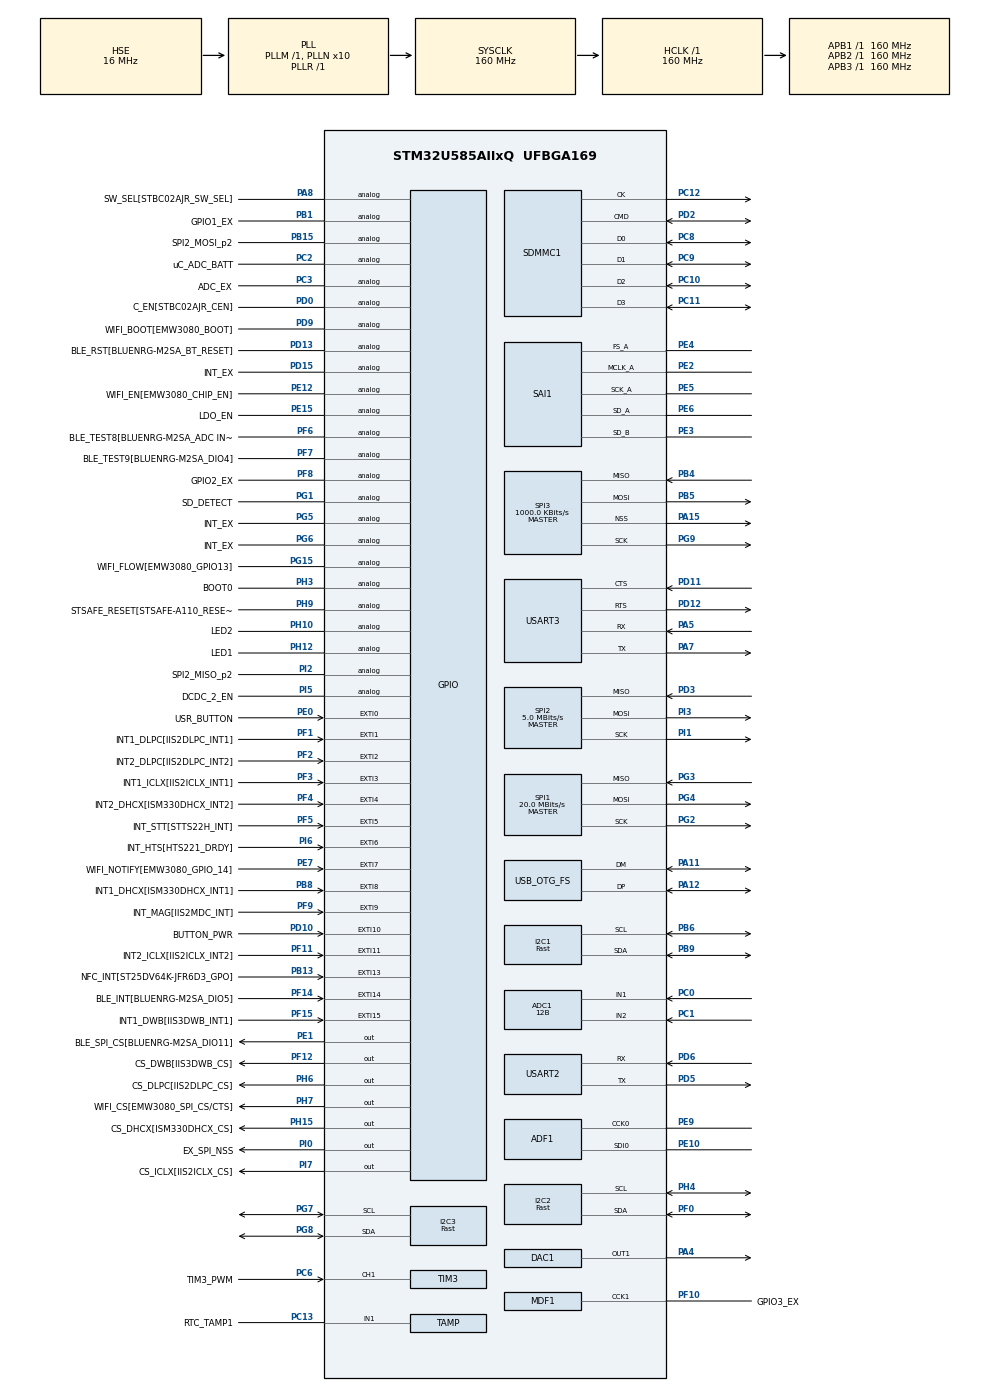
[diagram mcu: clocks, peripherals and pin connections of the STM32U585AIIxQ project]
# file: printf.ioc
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ADC1.ContinuousConvMode=ENABLE
ADC1.ConversionDataManagement=ADC_CONVERSIONDATA_MDF
ADC1.EnableInjectedConversion=DISABLE
ADC1.EnableRegularConversion=DISABLE
ADC1.NbrOfConversion=1
ADC1.Overrun=ADC_OVR_DATA_OVERWRITTEN
ADC1.Resolution=ADC_RESOLUTION_12B
ADC1.master=1
ADF1.MDF_COMPARAM_ActivationClockTrigger=ENABLE
ADF1.MDF_COMPARAM_ActivationOutputClock=ENABLE
ADF1.MDF_COMPARAM_Clock_Source=MDF_CLOCK_TRIG_TRGO
ADF1.MDF_COMPARAM_Divider=5
ADF1.MDF_DFLT0_AcquisitionMode=MDF_MODE_SYNC_CONT
ADF1.MDF_DFLT0_CIC_Mode=MDF_ONE_FILTER_SINC5
ADF1.MDF_DFLT0_Decimation=16
ADF1.MDF_DFLT0_Gain=1
ADF1.MDF_DFLT0_HighPassFilterActivation=ENABLE
ADF1.MDF_DFLT0_ReshapeFilterActivation=ENABLE
ADF1.MDF_SITF0_Mode_Display=MDF_SITF_NORMAL_SPI_MODE
ADF1.MDF_SITF0_Threshold=31
CORTEX_M33_NS.userName=CORTEX_M33
DAC1.DAC_Channel-DAC_OUT1_ExtAndInt=DAC_CHANNEL_1
GPDMA1.CIRCULARMODE_GPDMACH4=ENABLE
GPDMA1.CIRCULARMODE_GPDMACH5=ENABLE
GPDMA1.DATAALIGNEMENT_GPDMACH4=DMA_DATA_UNPACK
GPDMA1.DATAALIGNEMENT_GPDMACH5=DMA_DATA_UNPACK
GPDMA1.DATAHANDLING_GPDMACH4=ENABLE
GPDMA1.DATAHANDLING_GPDMACH5=ENABLE
GPDMA1.DESTDATAWIDTH_GPDMACH4=DMA_DEST_DATAWIDTH_HALFWORD
GPDMA1.DESTDATAWIDTH_GPDMACH5=DMA_DEST_DATAWIDTH_HALFWORD
GPDMA1.DESTINC_GPDMACH0=DMA_DINC_INCREMENTED
GPDMA1.DESTINC_GPDMACH2=DMA_DINC_INCREMENTED
GPDMA1.DESTINC_GPDMACH4=DMA_DINC_INCREMENTED
GPDMA1.DESTINC_GPDMACH5=DMA_DINC_INCREMENTED
GPDMA1.DIRECTION_GPDMACH1=DMA_MEMORY_TO_PERIPH
GPDMA1.DIRECTION_GPDMACH3=DMA_MEMORY_TO_PERIPH
GPDMA1.IPHANDLE_GPDMACH0-SIMPLEREQUEST_GPDMACH0=__NULL
GPDMA1.IPHANDLE_GPDMACH1-SIMPLEREQUEST_GPDMACH1=__NULL
GPDMA1.IPHANDLE_GPDMACH2-SIMPLEREQUEST_GPDMACH2=__NULL
GPDMA1.IPHANDLE_GPDMACH3-SIMPLEREQUEST_GPDMACH3=__NULL
GPDMA1.IPHANDLE_GPDMACH4-SIMPLEREQUEST_GPDMACH4=__NULL
GPDMA1.IPHANDLE_GPDMACH5-SIMPLEREQUEST_GPDMACH5=__NULL
GPDMA1.PRIORITY_LL_CIRCULAR_GPDMACH4=DMA_HIGH_PRIORITY
GPDMA1.PRIORITY_LL_CIRCULAR_GPDMACH5=DMA_HIGH_PRIORITY
GPDMA1.REQUEST_GPDMACH0=GPDMA1_REQUEST_SPI2_RX
GPDMA1.REQUEST_GPDMACH1=GPDMA1_REQUEST_SPI2_TX
GPDMA1.REQUEST_GPDMACH2=GPDMA1_REQUEST_I2C2_RX
GPDMA1.REQUEST_GPDMACH3=GPDMA1_REQUEST_I2C2_TX
GPDMA1.REQUEST_GPDMACH4=GPDMA1_REQUEST_MDF1_FLT0
GPDMA1.REQUEST_GPDMACH5=GPDMA1_REQUEST_ADF1_FLT0
GPDMA1.SRCDATAWIDTH_GPDMACH4=DMA_SRC_DATAWIDTH_HALFWORD
GPDMA1.SRCDATAWIDTH_GPDMACH5=DMA_SRC_DATAWIDTH_HALFWORD
GPDMA1.SRCINC_GPDMACH1=DMA_SINC_INCREMENTED
GPDMA1.SRCINC_GPDMACH3=DMA_SINC_INCREMENTED
GPDMA1.TRANSFERALLOCATEDPORTDEST_GPDMACH5=DMA_DEST_ALLOCATED_PORT1
GPDMA1.TRANSFEREVENTMODE_LL_CIRCULAR_GPDMACH4=DMA_TCEM_LAST_LL_ITEM_TRANSFER
GPDMA1.TRANSFEREVENTMODE_LL_CIRCULAR_GPDMACH5=DMA_TCEM_LAST_LL_ITEM_TRANSFER
GPDMA1.TRIGGERPOLARITY_GPDMACH0=DMA_TRIG_POLARITY_MASKED
GPDMA1.TRIGGERPOLARITY_GPDMACH1=DMA_TRIG_POLARITY_MASKED
I2C1.I2C_Speed_Mode=I2C_Fast
I2C1.Timing=0x00F07BFF
I2C2.I2C_Speed_Mode=I2C_Fast
I2C2.Timing=0x00F07BFF
I2C3.I2C_Speed_Mode=I2C_Fast
I2C3.Timing=0x00F07BFF
MDF1.MDF_DFLT0_CIC_Mode=MDF_ONE_FILTER_SINC5
MDF1.MDF_DFLT0_Decimation=4
MDF1.MDF_DFLT0_Gain=4
MDF1.MDF_DFLT0_HighPassFilterActivation=ENABLE
Mcu.Family=STM32U5
Mcu.Name=STM32U585AIIxQ
Mcu.Package=UFBGA169
NVIC.EXTI0_IRQn=true\:7\:0\:true\:false\:true\:true\:true\:true
NVIC.EXTI10_IRQn=true\:7\:0\:true\:false\:true\:true\:true\:true
NVIC.EXTI11_IRQn=true\:7\:0\:true\:false\:true\:true\:true\:true
NVIC.EXTI13_IRQn=true\:7\:0\:true\:false\:true\:true\:true\:true
NVIC.EXTI14_IRQn=true\:7\:0\:true\:false\:true\:true\:true\:true
NVIC.EXTI1_IRQn=true\:7\:0\:true\:false\:true\:true\:true\:true
NVIC.EXTI2_IRQn=true\:7\:0\:true\:false\:true\:true\:true\:true
NVIC.EXTI3_IRQn=true\:7\:0\:true\:false\:true\:true\:true\:true
NVIC.EXTI4_IRQn=true\:7\:0\:true\:false\:true\:true\:true\:true
NVIC.EXTI5_IRQn=true\:7\:0\:true\:false\:true\:true\:true\:true
NVIC.EXTI6_IRQn=true\:7\:0\:true\:false\:true\:true\:true\:true
NVIC.EXTI7_IRQn=true\:7\:0\:true\:false\:true\:true\:true\:true
NVIC.EXTI8_IRQn=true\:7\:0\:true\:false\:true\:true\:true\:true
NVIC.EXTI9_IRQn=true\:7\:0\:true\:false\:true\:true\:true\:true
NVIC.GPDMA1_Channel0_IRQn=true\:0\:0\:false\:false\:true\:true\:true\:true
NVIC.GPDMA1_Channel1_IRQn=true\:0\:0\:false\:false\:true\:true\:true\:true
NVIC.GPDMA1_Channel2_IRQn=true\:0\:0\:false\:false\:true\:false\:true\:true
NVIC.GPDMA1_Channel3_IRQn=true\:0\:0\:false\:false\:true\:false\:true\:true
NVIC.GPDMA1_Channel4_IRQn=true\:0\:0\:false\:false\:true\:false\:true\:true
NVIC.GPDMA1_Channel5_IRQn=true\:0\:0\:false\:false\:true\:false\:true\:true
NVIC.PriorityGroup=NVIC_PRIORITYGROUP_4
NVIC.SPI2_IRQn=true\:0\:0\:false\:false\:true\:false\:true\:true
PA11.GPIO_Speed=GPIO_SPEED_FREQ_VERY_HIGH
PA11.Mode=Device_Only
PA11.Signal=USB_OTG_FS_DM
PA12.GPIO_Speed=GPIO_SPEED_FREQ_VERY_HIGH
PA12.Mode=Device_Only
PA12.PinAttribute=Free
PA12.Signal=USB_OTG_FS_DP
PA13\ (JTMS/SWDIO).Mode=Trace_Asynchronous_SW
PA13\ (JTMS/SWDIO).Signal=DEBUG_JTMS-SWDIO
PA14\ (JTCK/SWCLK).Mode=Trace_Asynchronous_SW
PA14\ (JTCK/SWCLK).Signal=DEBUG_JTCK-SWCLK
PA15\ (JTDI).Mode=NSS_Signal_Hard_Output
PA15\ (JTDI).Signal=SPI3_NSS
PA4.Signal=COMP_DAC11_group
PA5.Mode=Asynchronous
PA5.PinAttribute=Free
PA5.Signal=USART3_RX
PA7.Mode=Asynchronous
PA7.Signal=USART3_TX
PA8.GPIO_Label=SW_SEL[STBC02AJR_SW_SEL]
PA8.PinAttribute=Free
PA8.Signal=GPIO_Analog
PB1.GPIO_Label=GPIO1_EX
PB1.Signal=GPIO_Analog
PB13.GPIO_Label=NFC_INT[ST25DV64K-JFR6D3_GPO]
PB13.Signal=GPXTI13
PB15.GPIO_Label=SPI2_MOSI_p2
PB15.Signal=GPIO_Analog
PB3\ (JTDO/TRACESWO).Mode=Trace_Asynchronous_SW
PB3\ (JTDO/TRACESWO).Signal=DEBUG_JTDO-SWO
PB4\ (NJTRST).Mode=Full_Duplex_Master
PB4\ (NJTRST).Signal=SPI3_MISO
PB5.Mode=Full_Duplex_Master
PB5.Signal=SPI3_MOSI
PB6.Mode=I2C
PB6.Signal=I2C1_SCL
PB8.GPIO_Label=INT1_DHCX[ISM330DHCX_INT1]
PB8.Signal=GPXTI8
PB9.Mode=I2C
PB9.Signal=I2C1_SDA
PC0.Mode=IN1-Single-Ended
PC0.Signal=ADC1_IN1
PC1.Mode=IN2-Single-Ended
PC1.Signal=ADC1_IN2
PC10.Mode=SD_4_bits_Wide_bus
PC10.Signal=SDMMC1_D2
PC11.Mode=SD_4_bits_Wide_bus
PC11.Signal=SDMMC1_D3
PC12.Mode=SD_4_bits_Wide_bus
PC12.Signal=SDMMC1_CK
PC13.GPIO_Label=RTC_TAMP1
PC13.Mode=Tamper_1_enabled0
PC13.Signal=TAMP_IN1
PC14-OSC32_IN\ (PC14).Mode=LSE-External-Oscillator
PC14-OSC32_IN\ (PC14).Signal=RCC_OSC32_IN
PC15-OSC32_OUT\ (PC15).Mode=LSE-External-Oscillator
PC15-OSC32_OUT\ (PC15).Signal=RCC_OSC32_OUT
PC2.GPIO_Label=uC_ADC_BATT
PC2.Signal=GPIO_Analog
PC3.GPIO_Label=ADC_EX
PC3.PinAttribute=Free
PC3.Signal=GPIO_Analog
PC6.GPIO_Label=TIM3_PWM
PC6.Signal=S_TIM3_CH1
PC8.Mode=SD_4_bits_Wide_bus
PC8.PinAttribute=Free
PC8.Signal=SDMMC1_D0
PC9.Mode=SD_4_bits_Wide_bus
PC9.PinAttribute=Free
PC9.Signal=SDMMC1_D1
PD0.GPIO_Label=C_EN[STBC02AJR_CEN]
PD0.Signal=GPIO_Analog
PD10.GPIO_Label=BUTTON_PWR
PD10.Signal=GPXTI10
PD11.Mode=CTS_RTS
PD11.Signal=USART3_CTS
PD12.Mode=CTS_RTS
PD12.Signal=USART3_RTS
PD13.GPIO_Label=BLE_RST[BLUENRG-M2SA_BT_RESET]
PD13.Signal=GPIO_Analog
PD15.GPIO_Label=INT_EX
PD15.PinAttribute=Free
PD15.Signal=GPIO_Analog
PD2.Mode=SD_4_bits_Wide_bus
PD2.Signal=SDMMC1_CMD
PD3.Mode=Full_Duplex_Master
PD3.Signal=SPI2_MISO
PD4.Signal=USART2_RTS
PD5.Mode=Asynchronous
PD5.Signal=USART2_TX
PD6.Mode=Asynchronous
PD6.Signal=USART2_RX
PD9.GPIO_Label=WIFI_BOOT[EMW3080_BOOT]
PD9.Signal=GPIO_Analog
PE0.GPIO_Label=USR_BUTTON
PE0.Signal=GPXTI0
PE1.GPIO_Label=BLE_SPI_CS[BLUENRG-M2SA_DIO11]
PE1.PinState=GPIO_PIN_SET
PE1.Signal=GPIO_Output
PE10.Mode=MOD_ADF_CCK
PE10.Signal=ADF1_SDI0
PE12.GPIO_Label=WIFI_EN[EMW3080_CHIP_EN]
PE12.Signal=GPIO_Analog
PE15.GPIO_Label=LDO_EN
PE15.Signal=GPIO_Analog
PE2.Mode=SAI_A_MasterWithClock
PE2.PinAttribute=Free
PE2.Signal=SAI1_MCLK_A
PE3.Mode=SAI_B_SyncSlave
PE3.Signal=SAI1_SD_B
PE4.Mode=SAI_A_MasterWithClock
PE4.Signal=SAI1_FS_A
PE5.Mode=SAI_A_MasterWithClock
PE5.Signal=SAI1_SCK_A
PE6.Mode=SAI_A_MasterWithClock
PE6.Signal=SAI1_SD_A
PE7.GPIO_Label=WIFI_NOTIFY[EMW3080_GPIO_14]
PE7.Signal=GPXTI7
PE9.Mode=MOD_MDF_CCK0
PE9.Signal=ADF1_CCK0
PF0.Mode=I2C
PF0.Signal=I2C2_SDA
PF1.GPIO_Label=INT1_DLPC[IIS2DLPC_INT1]
PF1.Signal=GPXTI1
PF10.GPIO_Label=GPIO3_EX
PF10.Mode=MOD_MDF_CCK1
PF10.Signal=MDF1_CCK1
PF11.GPIO_Label=INT2_ICLX[IIS2ICLX_INT2]
PF11.Signal=GPXTI11
PF12.GPIO_Label=CS_DWB[IIS3DWB_CS]
PF12.PinState=GPIO_PIN_SET
PF12.Signal=GPIO_Output
PF14.GPIO_Label=BLE_INT[BLUENRG-M2SA_DIO5]
PF14.Signal=GPXTI14
PF15.GPIO_Label=INT1_DWB[IIS3DWB_INT1]
PF15.Signal=GPXTI15
PF2.GPIO_Label=INT2_DLPC[IIS2DLPC_INT2]
PF2.Signal=GPXTI2
PF3.GPIO_Label=INT1_ICLX[IIS2ICLX_INT1]
PF3.PinAttribute=Free
PF3.Signal=GPXTI3
PF4.GPIO_Label=INT2_DHCX[ISM330DHCX_INT2]
PF4.PinAttribute=Free
PF4.Signal=GPXTI4
PF5.GPIO_Label=INT_STT[STTS22H_INT]
PF5.PinAttribute=Free
PF5.Signal=GPXTI5
PF6.GPIO_Label=BLE_TEST8[BLUENRG-M2SA_ADC IN 1]
PF6.Signal=GPIO_Analog
PF7.GPIO_Label=BLE_TEST9[BLUENRG-M2SA_DIO4]
PF7.PinAttribute=Free
PF7.Signal=GPIO_Analog
PF8.GPIO_Label=GPIO2_EX
PF8.Signal=GPIO_Analog
PF9.GPIO_Label=INT_MAG[IIS2MDC_INT]
PF9.PinAttribute=Free
PF9.Signal=GPXTI9
PG1.GPIO_Label=SD_DETECT
PG1.Signal=GPIO_Analog
PG15.GPIO_Label=WIFI_FLOW[EMW3080_GPIO13]
PG15.Signal=GPIO_Analog
PG2.Mode=Full_Duplex_Master
PG2.Signal=SPI1_SCK
PG3.Mode=Full_Duplex_Master
PG3.PinAttribute=Free
PG3.Signal=SPI1_MISO
PG4.Mode=Full_Duplex_Master
PG4.Signal=SPI1_MOSI
PG5.GPIO_Label=INT_EX
PG5.PinAttribute=Free
PG5.Signal=GPIO_Analog
PG6.GPIO_Label=INT_EX
PG6.Signal=GPIO_Analog
PG7.Mode=I2C
PG7.PinAttribute=Free
PG7.Signal=I2C3_SCL
PG8.Mode=I2C
PG8.Signal=I2C3_SDA
PG9.GPIO_PuPd=GPIO_PULLUP
PG9.Mode=Full_Duplex_Master
PG9.Signal=SPI3_SCK
PH0-OSC_IN\ (PH0).Mode=HSE-External-Oscillator
PH0-OSC_IN\ (PH0).Signal=RCC_OSC_IN
PH1-OSC_OUT\ (PH1).Mode=HSE-External-Oscillator
PH1-OSC_OUT\ (PH1).Signal=RCC_OSC_OUT
PH10.GPIO_Label=LED2
PH10.Signal=GPIO_Analog
PH12.GPIO_Label=LED1
PH12.Signal=GPIO_Analog
PH15.GPIO_Label=CS_DHCX[ISM330DHCX_CS]
PH15.PinState=GPIO_PIN_SET
PH15.Signal=GPIO_Output
PH3-BOOT0.GPIO_Label=BOOT0
PH3-BOOT0.Signal=GPIO_Analog
PH4.Mode=I2C
PH4.Signal=I2C2_SCL
PH6.GPIO_Label=CS_DLPC[IIS2DLPC_CS]
PH6.PinState=GPIO_PIN_SET
PH6.Signal=GPIO_Output
PH7.GPIO_Label=WIFI_CS[EMW3080_SPI_CS/CTS]
PH7.PinState=GPIO_PIN_SET
PH7.Signal=GPIO_Output
PH9.GPIO_Label=STSAFE_RESET[STSAFE-A110_RESET]
PH9.Signal=GPIO_Analog
PI0.GPIO_Label=EX_SPI_NSS
PI0.PinState=GPIO_PIN_SET
PI0.Signal=GPIO_Output
PI1.Mode=Full_Duplex_Master
PI1.Signal=SPI2_SCK
PI2.GPIO_Label=SPI2_MISO_p2
PI2.Signal=GPIO_Analog
PI3.Mode=Full_Duplex_Master
PI3.Signal=SPI2_MOSI
PI5.GPIO_Label=DCDC_2_EN
PI5.Signal=GPIO_Analog
PI6.GPIO_Label=INT_HTS[HTS221_DRDY]
PI6.PinAttribute=Free
PI6.Signal=GPXTI6
PI7.GPIO_Label=CS_ICLX[IIS2ICLX_CS]
PI7.PinState=GPIO_PIN_SET
PI7.Signal=GPIO_Output
ProjectManager.HeapSize=0x200
ProjectManager.StackSize=0x400
ProjectManager.TargetToolchain=STM32CubeIDE
RCC.ADCCLockSelection=RCC_ADCDACCLKSOURCE_PLL2
RCC.ADCFreq_Value=15360000
RCC.AHBFreq_Value=160000000
RCC.APB1Freq_Value=160000000
RCC.APB1TimFreq_Value=160000000
RCC.APB2Freq_Value=160000000
RCC.APB2TimFreq_Value=160000000
RCC.APB3Freq_Value=160000000
RCC.AdfClockSelection=RCC_ADF1CLKSOURCE_PLL3
RCC.CortexFreq_Value=160000000
RCC.DACCLockSelectionVirtual=RCC_DAC1CLKSOURCE_LSI
RCC.EPOD_VALUE=16000000
RCC.HCLKFreq_Value=160000000
RCC.HSE_VALUE=16000000
RCC.HSI48_VALUE=48000000
RCC.HSI_VALUE=16000000
RCC.LSIDIV_VALUE=32000
RCC.MSI_VALUE=4000000
RCC.MdfClockSelection=RCC_MDF1CLKSOURCE_PLL3
RCC.PLL1R=1
RCC.PLL2FRACN=0
RCC.PLL2M=2
RCC.PLL2N=48
RCC.PLL2Q=7
RCC.PLL2R=25
RCC.PLL2Source=RCC_PLLSOURCE_HSE
RCC.PLL3FRACN=0
RCC.PLL3M=2
RCC.PLL3N=48
RCC.PLL3Q=25
RCC.PLL3Source=RCC_PLLSOURCE_HSE
RCC.PLLFRACN=0
RCC.PLLN=10
RCC.PLLSourceVirtual=RCC_PLLSOURCE_HSE
RCC.SAI1CLockSelection=RCC_SAI1CLKSOURCE_PLL1
RCC.SDMMCClockSelection=RCC_SDMMCCLKSOURCE_CLK48
RCC.SPI2CLockSelection=RCC_SPI2CLKSOURCE_PCLK1
RCC.SPI3CLockSelection=RCC_SPI3CLKSOURCE_HSI
RCC.SYSCLKFreq_VALUE=160000000
RCC.SYSCLKSource=RCC_SYSCLKSOURCE_PLLCLK
RCC.USBFreq_Value=48000000
RCC.VCOOutputFreq_Value=160000000
SAI1.ErrorAudioFreq-SAI_A_MasterWithClock=-18.61 %
SAI1.Instance-SAI_A_MasterWithClock=SAI$Index_Block_A
SAI1.Instance-SAI_B_SyncSlave=SAI$Index_Block_B
SAI1.MckOutput-SAI_A_MasterWithClock=SAI_MCK_OUTPUT_ENABLE
SAI1.RealAudioFreq-SAI_A_MasterWithClock=156.25 KHz
SAI1.VirtualMode-SAI_A_MasterWithClock=VM_MASTER
SAI1.VirtualMode-SAI_B_SyncSlave=VM_SLAVE
SH.COMP_DAC11_group.0=DAC1_OUT1,DAC_OUT1_ExtAndInt
SH.S_TIM3_CH1.0=TIM3_CH1,Input_Capture1_from_TI1
SPI1.BaudRatePrescaler=SPI_BAUDRATEPRESCALER_8
SPI1.CLKPhase=SPI_PHASE_2EDGE
SPI1.CLKPolarity=SPI_POLARITY_HIGH
SPI1.CalculateBaudRate=20.0 MBits/s
SPI1.DataSize=SPI_DATASIZE_8BIT
SPI1.Direction=SPI_DIRECTION_2LINES
SPI1.Mode=SPI_MODE_MASTER
SPI1.VirtualType=VM_MASTER
SPI2.BaudRatePrescaler=SPI_BAUDRATEPRESCALER_32
SPI2.CLKPhase=SPI_PHASE_2EDGE
SPI2.CLKPolarity=SPI_POLARITY_HIGH
SPI2.CRCCalculation=SPI_CRCCALCULATION_DISABLE
SPI2.CalculateBaudRate=5.0 MBits/s
SPI2.DataSize=SPI_DATASIZE_8BIT
SPI2.Direction=SPI_DIRECTION_2LINES
SPI2.Mode=SPI_MODE_MASTER
SPI2.TriggerSelection=SPI_GRP1_GPDMA_CH1_TCF_TRG
SPI2.TriggerState=SPI_AUTO_MODE_DISABLE
SPI2.VirtualType=VM_MASTER
SPI3.BaudRatePrescaler=SPI_BAUDRATEPRESCALER_16
SPI3.CLKPhase=SPI_PHASE_2EDGE
SPI3.CLKPolarity=SPI_POLARITY_HIGH
SPI3.CalculateBaudRate=1000.0 KBits/s
SPI3.DataSize=SPI_DATASIZE_8BIT
SPI3.Direction=SPI_DIRECTION_2LINES
SPI3.Mode=SPI_MODE_MASTER
SPI3.VirtualNSS=VM_NSSHARD
SPI3.VirtualType=VM_MASTER
TIM3.Channel-Input_Capture1_from_TI1=TIM_CHANNEL_1
USART2.ClockPrescaler=PRESCALER_DIV1
USART2.VirtualMode-Asynchronous=VM_ASYNC
USART2.WordLength=WORDLENGTH_8B
USART3.VirtualMode-Asynchronous=VM_ASYNC
USB_OTG_FS.Sof_enable-Device_Only=ENABLE
USB_OTG_FS.VirtualMode=Device_Only
VP_GPDMA1_VS_GPDMACH0.Mode=SIMPLEREQUEST_GPDMACH0
VP_GPDMA1_VS_GPDMACH1.Mode=SIMPLEREQUEST_GPDMACH1
VP_GPDMA1_VS_GPDMACH2.Mode=SIMPLEREQUEST_GPDMACH2
VP_GPDMA1_VS_GPDMACH3.Mode=SIMPLEREQUEST_GPDMACH3
VP_GPDMA1_VS_GPDMACH4.Mode=SIMPLEREQUEST_GPDMACH4
VP_GPDMA1_VS_GPDMACH5.Mode=SIMPLEREQUEST_GPDMACH5
VP_ICACHE_VS_ICACHE.Mode=DirectMappedCache
VP_LPBAMQUEUE_VS_QUEUE.Mode=QUEUEMODE
VP_LPBAM_VS_SIG1.Mode=SmartRun
VP_LPBAM_VS_SIG4.Mode=LPDMA1
VP_MDF1_VS_MDF_DFLT0.Mode=MOD_MDF_DFLT0
VP_PWR_VS_DBSignals.Mode=DisableDeadBatterySignals
VP_PWR_VS_LPOM.Mode=PowerOptimisation
VP_PWR_VS_SECSignals.Mode=Security/Privilege
VP_RTC_VS_RTC_Activate.Mode=RTC_Enabled
board=STEVAL-STWINBX1

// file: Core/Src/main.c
/* USER CODE BEGIN Header */
/**
  ******************************************************************************
  * @file           : main.c
  * @brief          : Main program body
  ******************************************************************************
  * @attention
  *
  * Copyright (c) 2023 STMicroelectronics.
  * All rights reserved.
  *
  * This software is licensed under terms that can be found in the LICENSE file
  * in the root directory of this software component.
  * If no LICENSE file comes with this software, it is provided AS-IS.
  *
  ******************************************************************************
  */
/* USER CODE END Header */
#include "main.h"

/* USER CODE BEGIN Includes */
#include <stdio.h>

/* USER CODE END Includes */

ADC_HandleTypeDef hadc1;

MDF_HandleTypeDef AdfHandle0;
MDF_FilterConfigTypeDef AdfFilterConfig0;
MDF_HandleTypeDef MdfHandle0;
MDF_FilterConfigTypeDef MdfFilterConfig0;
DMA_NodeTypeDef Node_GPDMA1_Channel5;
DMA_QListTypeDef List_GPDMA1_Channel5;
DMA_HandleTypeDef handle_GPDMA1_Channel5;
DMA_NodeTypeDef Node_GPDMA1_Channel4;
DMA_QListTypeDef List_GPDMA1_Channel4;
DMA_HandleTypeDef handle_GPDMA1_Channel4;

DAC_HandleTypeDef hdac1;

I2C_HandleTypeDef hi2c1;
I2C_HandleTypeDef hi2c2;
I2C_HandleTypeDef hi2c3;
DMA_HandleTypeDef handle_GPDMA1_Channel3;
DMA_HandleTypeDef handle_GPDMA1_Channel2;

RTC_HandleTypeDef hrtc;

SAI_HandleTypeDef hsai_BlockA1;
SAI_HandleTypeDef hsai_BlockB1;

SD_HandleTypeDef hsd1;

SPI_HandleTypeDef hspi1;
SPI_HandleTypeDef hspi2;
SPI_HandleTypeDef hspi3;
DMA_HandleTypeDef handle_GPDMA1_Channel1;
DMA_HandleTypeDef handle_GPDMA1_Channel0;

TIM_HandleTypeDef htim3;

UART_HandleTypeDef huart2;
UART_HandleTypeDef huart3;

PCD_HandleTypeDef hpcd_USB_OTG_FS;

void SystemClock_Config(void);
void PeriphCommonClock_Config(void);
static void SystemPower_Config(void);
static void MX_GPIO_Init(void);
static void MX_GPDMA1_Init(void);
static void MX_ADC1_Init(void);
static void MX_ADF1_Init(void);
static void MX_MDF1_Init(void);
static void MX_DAC1_Init(void);
static void MX_I2C1_Init(void);
static void MX_I2C2_Init(void);
static void MX_I2C3_Init(void);
static void MX_ICACHE_Init(void);
static void MX_RTC_Init(void);
static void MX_SAI1_Init(void);
static void MX_SDMMC1_SD_Init(void);
static void MX_SPI1_Init(void);
static void MX_SPI2_Init(void);
static void MX_SPI3_Init(void);
static void MX_TAMP_RTC_Init(void);
static void MX_TIM3_Init(void);
static void MX_USART2_UART_Init(void);
static void MX_USART3_UART_Init(void);
static void MX_USB_OTG_FS_PCD_Init(void);

/* USER CODE BEGIN 0 */
#ifdef __GNUC__
#define PUTCHAR_PROTOTYPE int __io_putchar(int ch)
#else
#define PUTCHAR_PROTOTYPE int fputc(int ch, FILE *f)
#endif

PUTCHAR_PROTOTYPE
{
  HAL_UART_Transmit(&huart2, (uint8_t *)&ch, 1, HAL_MAX_DELAY);
  return ch;
}

/* USER CODE END 0 */

int main(void)
{

  /* MCU Configuration--------------------------------------------------------*/

  /* Reset of all peripherals, Initializes the Flash interface and the Systick. */
  HAL_Init();

  /* Configure the system clock */
  SystemClock_Config();

/* Configure the peripherals common clocks */
  PeriphCommonClock_Config();

  /* Configure the System Power */
  SystemPower_Config();

  /* Initialize all configured peripherals */
  MX_GPIO_Init();
  MX_GPDMA1_Init();
  MX_ADC1_Init();
  MX_ADF1_Init();
  MX_MDF1_Init();
  MX_DAC1_Init();
  MX_I2C1_Init();
  MX_I2C2_Init();
  MX_I2C3_Init();
  MX_ICACHE_Init();
  MX_RTC_Init();
  MX_SAI1_Init();
  MX_SDMMC1_SD_Init();
  MX_SPI1_Init();
  MX_SPI2_Init();
  MX_SPI3_Init();
  MX_TAMP_RTC_Init();
  MX_TIM3_Init();
  MX_USART2_UART_Init();
  MX_USART3_UART_Init();
  MX_USB_OTG_FS_PCD_Init();

  /* Infinite loop */
  while (1)
  {

    /* USER CODE BEGIN 3 */
	printf("Hello World!!!\n");
	HAL_Delay(1000);
  }
  /* USER CODE END 3 */
}

void SystemClock_Config(void)
{
  RCC_OscInitTypeDef RCC_OscInitStruct = {0};
  RCC_ClkInitTypeDef RCC_ClkInitStruct = {0};

  /** Configure the main internal regulator output voltage
  */
  if (HAL_PWREx_ControlVoltageScaling(PWR_REGULATOR_VOLTAGE_SCALE1) != HAL_OK)
  {
    Error_Handler();
  }

  /** Initializes the CPU, AHB and APB buses clocks
  */
  RCC_OscInitStruct.OscillatorType = RCC_OSCILLATORTYPE_HSI48|RCC_OSCILLATORTYPE_HSI
                              |RCC_OSCILLATORTYPE_LSI|RCC_OSCILLATORTYPE_HSE;
  RCC_OscInitStruct.HSEState = RCC_HSE_ON;
  RCC_OscInitStruct.HSIState = RCC_HSI_ON;
  RCC_OscInitStruct.HSI48State = RCC_HSI48_ON;
  RCC_OscInitStruct.HSICalibrationValue = RCC_HSICALIBRATION_DEFAULT;
  RCC_OscInitStruct.LSIState = RCC_LSI_ON;
  RCC_OscInitStruct.LSIDiv = RCC_LSI_DIV1;
  RCC_OscInitStruct.PLL.PLLState = RCC_PLL_ON;
  RCC_OscInitStruct.PLL.PLLSource = RCC_PLLSOURCE_HSE;
  RCC_OscInitStruct.PLL.PLLMBOOST = RCC_PLLMBOOST_DIV1;
  RCC_OscInitStruct.PLL.PLLM = 1;
  RCC_OscInitStruct.PLL.PLLN = 10;
  RCC_OscInitStruct.PLL.PLLP = 2;
  RCC_OscInitStruct.PLL.PLLQ = 2;
  RCC_OscInitStruct.PLL.PLLR = 1;
  RCC_OscInitStruct.PLL.PLLRGE = RCC_PLLVCIRANGE_1;
  RCC_OscInitStruct.PLL.PLLFRACN = 0;
  if (HAL_RCC_OscConfig(&RCC_OscInitStruct) != HAL_OK)
  {
    Error_Handler();
  }

  /** Initializes the CPU, AHB and APB buses clocks
  */
  RCC_ClkInitStruct.ClockType = RCC_CLOCKTYPE_HCLK|RCC_CLOCKTYPE_SYSCLK
                              |RCC_CLOCKTYPE_PCLK1|RCC_CLOCKTYPE_PCLK2
                              |RCC_CLOCKTYPE_PCLK3;
  RCC_ClkInitStruct.SYSCLKSource = RCC_SYSCLKSOURCE_PLLCLK;
  RCC_ClkInitStruct.AHBCLKDivider = RCC_SYSCLK_DIV1;
  RCC_ClkInitStruct.APB1CLKDivider = RCC_HCLK_DIV1;
  RCC_ClkInitStruct.APB2CLKDivider = RCC_HCLK_DIV1;
  RCC_ClkInitStruct.APB3CLKDivider = RCC_HCLK_DIV1;

  if (HAL_RCC_ClockConfig(&RCC_ClkInitStruct, FLASH_LATENCY_4) != HAL_OK)
  {
    Error_Handler();
  }
}

void PeriphCommonClock_Config(void)
{
  RCC_PeriphCLKInitTypeDef PeriphClkInit = {0};

  /** Initializes the common periph clock
  */
  PeriphClkInit.PeriphClockSelection = RCC_PERIPHCLK_MDF1|RCC_PERIPHCLK_ADF1
                              |RCC_PERIPHCLK_ADCDAC;
  PeriphClkInit.Mdf1ClockSelection = RCC_MDF1CLKSOURCE_PLL3;
  PeriphClkInit.Adf1ClockSelection = RCC_ADF1CLKSOURCE_PLL3;
  PeriphClkInit.AdcDacClockSelection = RCC_ADCDACCLKSOURCE_PLL2;
  PeriphClkInit.PLL3.PLL3Source = RCC_PLLSOURCE_HSE;
  PeriphClkInit.PLL3.PLL3M = 2;
  PeriphClkInit.PLL3.PLL3N = 48;
  PeriphClkInit.PLL3.PLL3P = 2;
  PeriphClkInit.PLL3.PLL3Q = 25;
  PeriphClkInit.PLL3.PLL3R = 2;
  PeriphClkInit.PLL3.PLL3RGE = RCC_PLLVCIRANGE_1;
  PeriphClkInit.PLL3.PLL3FRACN = 0;
  PeriphClkInit.PLL3.PLL3ClockOut = RCC_PLL3_DIVQ;
  PeriphClkInit.PLL2.PLL2Source = RCC_PLLSOURCE_HSE;
  PeriphClkInit.PLL2.PLL2M = 2;
  PeriphClkInit.PLL2.PLL2N = 48;
  PeriphClkInit.PLL2.PLL2P = 2;
  PeriphClkInit.PLL2.PLL2Q = 7;
  PeriphClkInit.PLL2.PLL2R = 25;
  PeriphClkInit.PLL2.PLL2RGE = RCC_PLLVCIRANGE_1;
  PeriphClkInit.PLL2.PLL2FRACN = 0;
  PeriphClkInit.PLL2.PLL2ClockOut = RCC_PLL2_DIVR;
  if (HAL_RCCEx_PeriphCLKConfig(&PeriphClkInit) != HAL_OK)
  {
    Error_Handler();
  }
}

/**
  * @brief Power Configuration
  * @retval None
  */
static void SystemPower_Config(void)
{
  HAL_PWREx_EnableVddIO2();

  /*
   * Disable the internal Pull-Up in Dead Battery pins of UCPD peripheral
   */
  HAL_PWREx_DisableUCPDDeadBattery();
}

static void MX_ADC1_Init(void)
{

  /** Common config
  */
  hadc1.Instance = ADC1;
  hadc1.Init.ClockPrescaler = ADC_CLOCK_ASYNC_DIV1;
  hadc1.Init.Resolution = ADC_RESOLUTION_12B;
  hadc1.Init.GainCompensation = 0;
  hadc1.Init.ScanConvMode = ADC_SCAN_DISABLE;
  hadc1.Init.EOCSelection = ADC_EOC_SINGLE_CONV;
  hadc1.Init.LowPowerAutoWait = DISABLE;
  hadc1.Init.ContinuousConvMode = ENABLE;
  hadc1.Init.NbrOfConversion = 1;
  hadc1.Init.DiscontinuousConvMode = DISABLE;
  hadc1.Init.DMAContinuousRequests = DISABLE;
  hadc1.Init.TriggerFrequencyMode = ADC_TRIGGER_FREQ_HIGH;
  hadc1.Init.Overrun = ADC_OVR_DATA_OVERWRITTEN;
  hadc1.Init.LeftBitShift = ADC_LEFTBITSHIFT_NONE;
  hadc1.Init.ConversionDataManagement = ADC_CONVERSIONDATA_MDF;
  hadc1.Init.OversamplingMode = DISABLE;
  if (HAL_ADC_Init(&hadc1) != HAL_OK)
  {
    Error_Handler();
  }

}

static void MX_ADF1_Init(void)
{

  /**
    AdfHandle0 structure initialization and HAL_MDF_Init function call
  */
  AdfHandle0.Instance = ADF1_Filter0;
  AdfHandle0.Init.CommonParam.ProcClockDivider = 1;
  AdfHandle0.Init.CommonParam.OutputClock.Activation = ENABLE;
  AdfHandle0.Init.CommonParam.OutputClock.Pins = MDF_OUTPUT_CLOCK_0;
  AdfHandle0.Init.CommonParam.OutputClock.Divider = 5;
  AdfHandle0.Init.CommonParam.OutputClock.Trigger.Activation = ENABLE;
  AdfHandle0.Init.CommonParam.OutputClock.Trigger.Source = MDF_CLOCK_TRIG_TRGO;
  AdfHandle0.Init.CommonParam.OutputClock.Trigger.Edge = MDF_CLOCK_TRIG_FALLING_EDGE;
  AdfHandle0.Init.SerialInterface.Activation = ENABLE;
  AdfHandle0.Init.SerialInterface.Mode = MDF_SITF_NORMAL_SPI_MODE;
  AdfHandle0.Init.SerialInterface.ClockSource = MDF_SITF_CCK0_SOURCE;
  AdfHandle0.Init.SerialInterface.Threshold = 31;
  AdfHandle0.Init.FilterBistream = MDF_BITSTREAM0_FALLING;
  if (HAL_MDF_Init(&AdfHandle0) != HAL_OK)
  {
    Error_Handler();
  }

  /**
    AdfFilterConfig0 structure initialization

    WARNING : only structure is filled, no specific init function call for filter
  */
  AdfFilterConfig0.DataSource = MDF_DATA_SOURCE_BSMX;
  AdfFilterConfig0.Delay = 0;
  AdfFilterConfig0.CicMode = MDF_ONE_FILTER_SINC5;
  AdfFilterConfig0.DecimationRatio = 16;
  AdfFilterConfig0.Gain = 1;
  AdfFilterConfig0.ReshapeFilter.Activation = ENABLE;
  AdfFilterConfig0.ReshapeFilter.DecimationRatio = MDF_RSF_DECIMATION_RATIO_4;
  AdfFilterConfig0.HighPassFilter.Activation = ENABLE;
  AdfFilterConfig0.HighPassFilter.CutOffFrequency = MDF_HPF_CUTOFF_0_000625FPCM;
  AdfFilterConfig0.SoundActivity.Activation = DISABLE;
  AdfFilterConfig0.AcquisitionMode = MDF_MODE_SYNC_CONT;
  AdfFilterConfig0.FifoThreshold = MDF_FIFO_THRESHOLD_NOT_EMPTY;
  AdfFilterConfig0.DiscardSamples = 0;
  AdfFilterConfig0.Trigger.Source = MDF_CLOCK_TRIG_TRGO;
  AdfFilterConfig0.Trigger.Edge = MDF_FILTER_TRIG_RISING_EDGE;

}

static void MX_MDF1_Init(void)
{

  /**
    MdfHandle0 structure initialization and HAL_MDF_Init function call
  */
  MdfHandle0.Instance = MDF1_Filter0;
  MdfHandle0.Init.CommonParam.InterleavedFilters = 0;
  MdfHandle0.Init.CommonParam.ProcClockDivider = 1;
  MdfHandle0.Init.CommonParam.OutputClock.Activation = DISABLE;
  MdfHandle0.Init.SerialInterface.Activation = DISABLE;
  if (HAL_MDF_Init(&MdfHandle0) != HAL_OK)
  {
    Error_Handler();
  }

  /**
    MdfFilterConfig0, MdfOldConfig0 and/or MdfScdConfig0 structures initialization

    WARNING : only structures are filled, no specific init function call for filter
  */
  MdfFilterConfig0.DataSource = MDF_DATA_SOURCE_ADCITF1;
  MdfFilterConfig0.Delay = 0;
  MdfFilterConfig0.CicMode = MDF_ONE_FILTER_SINC5;
  MdfFilterConfig0.DecimationRatio = 4;
  MdfFilterConfig0.Offset = 0;
  MdfFilterConfig0.Gain = 4;
  MdfFilterConfig0.ReshapeFilter.Activation = DISABLE;
  MdfFilterConfig0.HighPassFilter.Activation = ENABLE;
  MdfFilterConfig0.HighPassFilter.CutOffFrequency = MDF_HPF_CUTOFF_0_000625FPCM;
  MdfFilterConfig0.Integrator.Activation = DISABLE;
  MdfFilterConfig0.SoundActivity.Activation = DISABLE;
  MdfFilterConfig0.AcquisitionMode = MDF_MODE_ASYNC_CONT;
  MdfFilterConfig0.FifoThreshold = MDF_FIFO_THRESHOLD_NOT_EMPTY;
  MdfFilterConfig0.DiscardSamples = 0;

}

static void MX_DAC1_Init(void)
{

  DAC_ChannelConfTypeDef sConfig = {0};
  DAC_AutonomousModeConfTypeDef sAutonomousMode = {0};

  /** DAC Initialization
  */
  hdac1.Instance = DAC1;
  if (HAL_DAC_Init(&hdac1) != HAL_OK)
  {
    Error_Handler();
  }

  /** DAC channel OUT1 config
  */
  sConfig.DAC_HighFrequency = DAC_HIGH_FREQUENCY_INTERFACE_MODE_DISABLE;
  sConfig.DAC_DMADoubleDataMode = DISABLE;
  sConfig.DAC_SignedFormat = DISABLE;
  sConfig.DAC_SampleAndHold = DAC_SAMPLEANDHOLD_DISABLE;
  sConfig.DAC_Trigger = DAC_TRIGGER_NONE;
  sConfig.DAC_OutputBuffer = DAC_OUTPUTBUFFER_ENABLE;
  sConfig.DAC_ConnectOnChipPeripheral = DAC_CHIPCONNECT_BOTH;
  sConfig.DAC_UserTrimming = DAC_TRIMMING_FACTORY;
  if (HAL_DAC_ConfigChannel(&hdac1, &sConfig, DAC_CHANNEL_1) != HAL_OK)
  {
    Error_Handler();
  }

  /** Configure Autonomous Mode
  */
  sAutonomousMode.AutonomousModeState = DAC_AUTONOMOUS_MODE_DISABLE;
  if (HAL_DACEx_SetConfigAutonomousMode(&hdac1, &sAutonomousMode) != HAL_OK)
  {
    Error_Handler();
  }

}

static void MX_GPDMA1_Init(void)
{

  /* Peripheral clock enable */
  __HAL_RCC_GPDMA1_CLK_ENABLE();

  /* GPDMA1 interrupt Init */
    HAL_NVIC_SetPriority(GPDMA1_Channel0_IRQn, 0, 0);
    HAL_NVIC_EnableIRQ(GPDMA1_Channel0_IRQn);
    HAL_NVIC_SetPriority(GPDMA1_Channel1_IRQn, 0, 0);
    HAL_NVIC_EnableIRQ(GPDMA1_Channel1_IRQn);
    HAL_NVIC_SetPriority(GPDMA1_Channel2_IRQn, 0, 0);
    HAL_NVIC_EnableIRQ(GPDMA1_Channel2_IRQn);
    HAL_NVIC_SetPriority(GPDMA1_Channel3_IRQn, 0, 0);
    HAL_NVIC_EnableIRQ(GPDMA1_Channel3_IRQn);
    HAL_NVIC_SetPriority(GPDMA1_Channel4_IRQn, 0, 0);
    HAL_NVIC_EnableIRQ(GPDMA1_Channel4_IRQn);
    HAL_NVIC_SetPriority(GPDMA1_Channel5_IRQn, 0, 0);
    HAL_NVIC_EnableIRQ(GPDMA1_Channel5_IRQn);

}

static void MX_I2C1_Init(void)
{

  hi2c1.Instance = I2C1;
  hi2c1.Init.Timing = 0x00F07BFF;
  hi2c1.Init.OwnAddress1 = 0;
  hi2c1.Init.AddressingMode = I2C_ADDRESSINGMODE_7BIT;
  hi2c1.Init.DualAddressMode = I2C_DUALADDRESS_DISABLE;
  hi2c1.Init.OwnAddress2 = 0;
  hi2c1.Init.OwnAddress2Masks = I2C_OA2_NOMASK;
  hi2c1.Init.GeneralCallMode = I2C_GENERALCALL_DISABLE;
  hi2c1.Init.NoStretchMode = I2C_NOSTRETCH_DISABLE;
  if (HAL_I2C_Init(&hi2c1) != HAL_OK)
  {
    Error_Handler();
  }

  /** Configure Analogue filter
  */
  if (HAL_I2CEx_ConfigAnalogFilter(&hi2c1, I2C_ANALOGFILTER_ENABLE) != HAL_OK)
  {
    Error_Handler();
  }

  /** Configure Digital filter
  */
  if (HAL_I2CEx_ConfigDigitalFilter(&hi2c1, 0) != HAL_OK)
  {
    Error_Handler();
  }

}

static void MX_I2C2_Init(void)
{

  hi2c2.Instance = I2C2;
  hi2c2.Init.Timing = 0x00F07BFF;
  hi2c2.Init.OwnAddress1 = 0;
  hi2c2.Init.AddressingMode = I2C_ADDRESSINGMODE_7BIT;
  hi2c2.Init.DualAddressMode = I2C_DUALADDRESS_DISABLE;
  hi2c2.Init.OwnAddress2 = 0;
  hi2c2.Init.OwnAddress2Masks = I2C_OA2_NOMASK;
  hi2c2.Init.GeneralCallMode = I2C_GENERALCALL_DISABLE;
  hi2c2.Init.NoStretchMode = I2C_NOSTRETCH_DISABLE;
  if (HAL_I2C_Init(&hi2c2) != HAL_OK)
  {
    Error_Handler();
  }

  /** Configure Analogue filter
  */
  if (HAL_I2CEx_ConfigAnalogFilter(&hi2c2, I2C_ANALOGFILTER_ENABLE) != HAL_OK)
  {
    Error_Handler();
  }

  /** Configure Digital filter
  */
  if (HAL_I2CEx_ConfigDigitalFilter(&hi2c2, 0) != HAL_OK)
  {
    Error_Handler();
  }

}

static void MX_I2C3_Init(void)
{

  hi2c3.Instance = I2C3;
  hi2c3.Init.Timing = 0x00F07BFF;
  hi2c3.Init.OwnAddress1 = 0;
  hi2c3.Init.AddressingMode = I2C_ADDRESSINGMODE_7BIT;
  hi2c3.Init.DualAddressMode = I2C_DUALADDRESS_DISABLE;
  hi2c3.Init.OwnAddress2 = 0;
  hi2c3.Init.OwnAddress2Masks = I2C_OA2_NOMASK;
  hi2c3.Init.GeneralCallMode = I2C_GENERALCALL_DISABLE;
  hi2c3.Init.NoStretchMode = I2C_NOSTRETCH_DISABLE;
  if (HAL_I2C_Init(&hi2c3) != HAL_OK)
  {
    Error_Handler();
  }

  /** Configure Analogue filter
  */
  if (HAL_I2CEx_ConfigAnalogFilter(&hi2c3, I2C_ANALOGFILTER_ENABLE) != HAL_OK)
  {
    Error_Handler();
  }

  /** Configure Digital filter
  */
  if (HAL_I2CEx_ConfigDigitalFilter(&hi2c3, 0) != HAL_OK)
  {
    Error_Handler();
  }

}

static void MX_ICACHE_Init(void)
{

  /** Enable instruction cache in 1-way (direct mapped cache)
  */
  if (HAL_ICACHE_ConfigAssociativityMode(ICACHE_1WAY) != HAL_OK)
  {
    Error_Handler();
  }
  if (HAL_ICACHE_Enable() != HAL_OK)
  {
    Error_Handler();
  }

}

static void MX_RTC_Init(void)
{

  RTC_PrivilegeStateTypeDef privilegeState = {0};

  /** Initialize RTC Only
  */
  hrtc.Instance = RTC;
  hrtc.Init.HourFormat = RTC_HOURFORMAT_24;
  hrtc.Init.AsynchPrediv = 127;
  hrtc.Init.SynchPrediv = 255;
  hrtc.Init.OutPut = RTC_OUTPUT_DISABLE;
  hrtc.Init.OutPutRemap = RTC_OUTPUT_REMAP_NONE;
  hrtc.Init.OutPutPolarity = RTC_OUTPUT_POLARITY_HIGH;
  hrtc.Init.OutPutType = RTC_OUTPUT_TYPE_OPENDRAIN;
  hrtc.Init.OutPutPullUp = RTC_OUTPUT_PULLUP_NONE;
  hrtc.Init.BinMode = RTC_BINARY_NONE;
  if (HAL_RTC_Init(&hrtc) != HAL_OK)
  {
    Error_Handler();
  }
  privilegeState.rtcPrivilegeFull = RTC_PRIVILEGE_FULL_NO;
  privilegeState.backupRegisterPrivZone = RTC_PRIVILEGE_BKUP_ZONE_NONE;
  privilegeState.backupRegisterStartZone2 = RTC_BKP_DR0;
  privilegeState.backupRegisterStartZone3 = RTC_BKP_DR0;
  if (HAL_RTCEx_PrivilegeModeSet(&hrtc, &privilegeState) != HAL_OK)
  {
    Error_Handler();
  }

}

static void MX_SAI1_Init(void)
{

  hsai_BlockA1.Instance = SAI1_Block_A;
  hsai_BlockA1.Init.Protocol = SAI_FREE_PROTOCOL;
  hsai_BlockA1.Init.AudioMode = SAI_MODEMASTER_TX;
  hsai_BlockA1.Init.DataSize = SAI_DATASIZE_8;
  hsai_BlockA1.Init.FirstBit = SAI_FIRSTBIT_MSB;
  hsai_BlockA1.Init.ClockStrobing = SAI_CLOCKSTROBING_FALLINGEDGE;
  hsai_BlockA1.Init.Synchro = SAI_ASYNCHRONOUS;
  hsai_BlockA1.Init.OutputDrive = SAI_OUTPUTDRIVE_DISABLE;
  hsai_BlockA1.Init.NoDivider = SAI_MASTERDIVIDER_ENABLE;
  hsai_BlockA1.Init.FIFOThreshold = SAI_FIFOTHRESHOLD_EMPTY;
  hsai_BlockA1.Init.AudioFrequency = SAI_AUDIO_FREQUENCY_192K;
  hsai_BlockA1.Init.SynchroExt = SAI_SYNCEXT_DISABLE;
  hsai_BlockA1.Init.MckOutput = SAI_MCK_OUTPUT_ENABLE;
  hsai_BlockA1.Init.MonoStereoMode = SAI_STEREOMODE;
  hsai_BlockA1.Init.CompandingMode = SAI_NOCOMPANDING;
  hsai_BlockA1.Init.TriState = SAI_OUTPUT_NOTRELEASED;
  hsai_BlockA1.Init.PdmInit.Activation = DISABLE;
  hsai_BlockA1.Init.PdmInit.MicPairsNbr = 1;
  hsai_BlockA1.Init.PdmInit.ClockEnable = SAI_PDM_CLOCK1_ENABLE;
  hsai_BlockA1.FrameInit.FrameLength = 8;
  hsai_BlockA1.FrameInit.ActiveFrameLength = 1;
  hsai_BlockA1.FrameInit.FSDefinition = SAI_FS_STARTFRAME;
  hsai_BlockA1.FrameInit.FSPolarity = SAI_FS_ACTIVE_LOW;
  hsai_BlockA1.FrameInit.FSOffset = SAI_FS_FIRSTBIT;
  hsai_BlockA1.SlotInit.FirstBitOffset = 0;
  hsai_BlockA1.SlotInit.SlotSize = SAI_SLOTSIZE_DATASIZE;
  hsai_BlockA1.SlotInit.SlotNumber = 1;
  hsai_BlockA1.SlotInit.SlotActive = 0x00000000;
  if (HAL_SAI_Init(&hsai_BlockA1) != HAL_OK)
  {
    Error_Handler();
  }
  hsai_BlockB1.Instance = SAI1_Block_B;
  hsai_BlockB1.Init.Protocol = SAI_FREE_PROTOCOL;
  hsai_BlockB1.Init.AudioMode = SAI_MODESLAVE_RX;
  hsai_BlockB1.Init.DataSize = SAI_DATASIZE_8;
  hsai_BlockB1.Init.FirstBit = SAI_FIRSTBIT_MSB;
  hsai_BlockB1.Init.ClockStrobing = SAI_CLOCKSTROBING_FALLINGEDGE;
  hsai_BlockB1.Init.Synchro = SAI_SYNCHRONOUS;
  hsai_BlockB1.Init.OutputDrive = SAI_OUTPUTDRIVE_DISABLE;
  hsai_BlockB1.Init.FIFOThreshold = SAI_FIFOTHRESHOLD_EMPTY;
  hsai_BlockB1.Init.SynchroExt = SAI_SYNCEXT_DISABLE;
  hsai_BlockB1.Init.MckOutput = SAI_MCK_OUTPUT_ENABLE;
  hsai_BlockB1.Init.MonoStereoMode = SAI_STEREOMODE;
  hsai_BlockB1.Init.CompandingMode = SAI_NOCOMPANDING;
  hsai_BlockB1.Init.TriState = SAI_OUTPUT_NOTRELEASED;
  hsai_BlockB1.Init.PdmInit.Activation = DISABLE;
  hsai_BlockB1.Init.PdmInit.MicPairsNbr = 1;
  hsai_BlockB1.Init.PdmInit.ClockEnable = SAI_PDM_CLOCK1_ENABLE;
  hsai_BlockB1.FrameInit.FrameLength = 8;
  hsai_BlockB1.FrameInit.ActiveFrameLength = 1;
  hsai_BlockB1.FrameInit.FSDefinition = SAI_FS_STARTFRAME;
  hsai_BlockB1.FrameInit.FSPolarity = SAI_FS_ACTIVE_LOW;
  hsai_BlockB1.FrameInit.FSOffset = SAI_FS_FIRSTBIT;
  hsai_BlockB1.SlotInit.FirstBitOffset = 0;
  hsai_BlockB1.SlotInit.SlotSize = SAI_SLOTSIZE_DATASIZE;
  hsai_BlockB1.SlotInit.SlotNumber = 1;
  hsai_BlockB1.SlotInit.SlotActive = 0x00000000;
  if (HAL_SAI_Init(&hsai_BlockB1) != HAL_OK)
  {
    Error_Handler();
  }

}

static void MX_SDMMC1_SD_Init(void)
{

  hsd1.Instance = SDMMC1;
  hsd1.Init.ClockEdge = SDMMC_CLOCK_EDGE_RISING;
  hsd1.Init.ClockPowerSave = SDMMC_CLOCK_POWER_SAVE_DISABLE;
  hsd1.Init.BusWide = SDMMC_BUS_WIDE_4B;
  hsd1.Init.HardwareFlowControl = SDMMC_HARDWARE_FLOW_CONTROL_DISABLE;
  hsd1.Init.ClockDiv = 0;
  if (HAL_SD_Init(&hsd1) != HAL_OK)
  {
    Error_Handler();
  }

}

static void MX_SPI1_Init(void)
{

  SPI_AutonomousModeConfTypeDef HAL_SPI_AutonomousMode_Cfg_Struct = {0};

  /* SPI1 parameter configuration*/
  hspi1.Instance = SPI1;
  hspi1.Init.Mode = SPI_MODE_MASTER;
  hspi1.Init.Direction = SPI_DIRECTION_2LINES;
  hspi1.Init.DataSize = SPI_DATASIZE_8BIT;
  hspi1.Init.CLKPolarity = SPI_POLARITY_HIGH;
  hspi1.Init.CLKPhase = SPI_PHASE_2EDGE;
  hspi1.Init.NSS = SPI_NSS_SOFT;
  hspi1.Init.BaudRatePrescaler = SPI_BAUDRATEPRESCALER_8;
  hspi1.Init.FirstBit = SPI_FIRSTBIT_MSB;
  hspi1.Init.TIMode = SPI_TIMODE_DISABLE;
  hspi1.Init.CRCCalculation = SPI_CRCCALCULATION_DISABLE;
  hspi1.Init.CRCPolynomial = 0x7;
  hspi1.Init.NSSPMode = SPI_NSS_PULSE_DISABLE;
  hspi1.Init.NSSPolarity = SPI_NSS_POLARITY_LOW;
  hspi1.Init.FifoThreshold = SPI_FIFO_THRESHOLD_01DATA;
  hspi1.Init.MasterSSIdleness = SPI_MASTER_SS_IDLENESS_00CYCLE;
  hspi1.Init.MasterInterDataIdleness = SPI_MASTER_INTERDATA_IDLENESS_00CYCLE;
  hspi1.Init.MasterReceiverAutoSusp = SPI_MASTER_RX_AUTOSUSP_DISABLE;
  hspi1.Init.MasterKeepIOState = SPI_MASTER_KEEP_IO_STATE_DISABLE;
  hspi1.Init.IOSwap = SPI_IO_SWAP_DISABLE;
  hspi1.Init.ReadyMasterManagement = SPI_RDY_MASTER_MANAGEMENT_INTERNALLY;
  hspi1.Init.ReadyPolarity = SPI_RDY_POLARITY_HIGH;
  if (HAL_SPI_Init(&hspi1) != HAL_OK)
  {
    Error_Handler();
  }
  HAL_SPI_AutonomousMode_Cfg_Struct.TriggerState = SPI_AUTO_MODE_DISABLE;
  HAL_SPI_AutonomousMode_Cfg_Struct.TriggerSelection = SPI_GRP1_GPDMA_CH0_TCF_TRG;
  HAL_SPI_AutonomousMode_Cfg_Struct.TriggerPolarity = SPI_TRIG_POLARITY_RISING;
  if (HAL_SPIEx_SetConfigAutonomousMode(&hspi1, &HAL_SPI_AutonomousMode_Cfg_Struct) != HAL_OK)
  {
    Error_Handler();
  }

}

static void MX_SPI2_Init(void)
{

  SPI_AutonomousModeConfTypeDef HAL_SPI_AutonomousMode_Cfg_Struct = {0};

  /* SPI2 parameter configuration*/
  hspi2.Instance = SPI2;
  hspi2.Init.Mode = SPI_MODE_MASTER;
  hspi2.Init.Direction = SPI_DIRECTION_2LINES;
  hspi2.Init.DataSize = SPI_DATASIZE_8BIT;
  hspi2.Init.CLKPolarity = SPI_POLARITY_HIGH;
  hspi2.Init.CLKPhase = SPI_PHASE_2EDGE;
  hspi2.Init.NSS = SPI_NSS_SOFT;
  hspi2.Init.BaudRatePrescaler = SPI_BAUDRATEPRESCALER_32;
  hspi2.Init.FirstBit = SPI_FIRSTBIT_MSB;
  hspi2.Init.TIMode = SPI_TIMODE_DISABLE;
  hspi2.Init.CRCCalculation = SPI_CRCCALCULATION_DISABLE;
  hspi2.Init.CRCPolynomial = 0x7;
  hspi2.Init.NSSPMode = SPI_NSS_PULSE_DISABLE;
  hspi2.Init.NSSPolarity = SPI_NSS_POLARITY_LOW;
  hspi2.Init.FifoThreshold = SPI_FIFO_THRESHOLD_01DATA;
  hspi2.Init.MasterSSIdleness = SPI_MASTER_SS_IDLENESS_00CYCLE;
  hspi2.Init.MasterInterDataIdleness = SPI_MASTER_INTERDATA_IDLENESS_00CYCLE;
  hspi2.Init.MasterReceiverAutoSusp = SPI_MASTER_RX_AUTOSUSP_DISABLE;
  hspi2.Init.MasterKeepIOState = SPI_MASTER_KEEP_IO_STATE_DISABLE;
  hspi2.Init.IOSwap = SPI_IO_SWAP_DISABLE;
  hspi2.Init.ReadyMasterManagement = SPI_RDY_MASTER_MANAGEMENT_INTERNALLY;
  hspi2.Init.ReadyPolarity = SPI_RDY_POLARITY_HIGH;
  if (HAL_SPI_Init(&hspi2) != HAL_OK)
  {
    Error_Handler();
  }
  HAL_SPI_AutonomousMode_Cfg_Struct.TriggerState = SPI_AUTO_MODE_DISABLE;
  HAL_SPI_AutonomousMode_Cfg_Struct.TriggerSelection = SPI_GRP1_GPDMA_CH1_TCF_TRG;
  HAL_SPI_AutonomousMode_Cfg_Struct.TriggerPolarity = SPI_TRIG_POLARITY_RISING;
  if (HAL_SPIEx_SetConfigAutonomousMode(&hspi2, &HAL_SPI_AutonomousMode_Cfg_Struct) != HAL_OK)
  {
    Error_Handler();
  }

}

static void MX_SPI3_Init(void)
{

  SPI_AutonomousModeConfTypeDef HAL_SPI_AutonomousMode_Cfg_Struct = {0};

  /* SPI3 parameter configuration*/
  hspi3.Instance = SPI3;
  hspi3.Init.Mode = SPI_MODE_MASTER;
  hspi3.Init.Direction = SPI_DIRECTION_2LINES;
  hspi3.Init.DataSize = SPI_DATASIZE_8BIT;
  hspi3.Init.CLKPolarity = SPI_POLARITY_HIGH;
  hspi3.Init.CLKPhase = SPI_PHASE_2EDGE;
  hspi3.Init.NSS = SPI_NSS_HARD_OUTPUT;
  hspi3.Init.BaudRatePrescaler = SPI_BAUDRATEPRESCALER_16;
  hspi3.Init.FirstBit = SPI_FIRSTBIT_MSB;
  hspi3.Init.TIMode = SPI_TIMODE_DISABLE;
  hspi3.Init.CRCCalculation = SPI_CRCCALCULATION_DISABLE;
  hspi3.Init.CRCPolynomial = 0x7;
  hspi3.Init.NSSPMode = SPI_NSS_PULSE_DISABLE;
  hspi3.Init.NSSPolarity = SPI_NSS_POLARITY_LOW;
  hspi3.Init.FifoThreshold = SPI_FIFO_THRESHOLD_01DATA;
  hspi3.Init.MasterSSIdleness = SPI_MASTER_SS_IDLENESS_00CYCLE;
  hspi3.Init.MasterInterDataIdleness = SPI_MASTER_INTERDATA_IDLENESS_00CYCLE;
  hspi3.Init.MasterReceiverAutoSusp = SPI_MASTER_RX_AUTOSUSP_DISABLE;
  hspi3.Init.MasterKeepIOState = SPI_MASTER_KEEP_IO_STATE_DISABLE;
  hspi3.Init.IOSwap = SPI_IO_SWAP_DISABLE;
  hspi3.Init.ReadyMasterManagement = SPI_RDY_MASTER_MANAGEMENT_INTERNALLY;
  hspi3.Init.ReadyPolarity = SPI_RDY_POLARITY_HIGH;
  if (HAL_SPI_Init(&hspi3) != HAL_OK)
  {
    Error_Handler();
  }
  HAL_SPI_AutonomousMode_Cfg_Struct.TriggerState = SPI_AUTO_MODE_DISABLE;
  HAL_SPI_AutonomousMode_Cfg_Struct.TriggerSelection = SPI_GRP1_GPDMA_CH0_TCF_TRG;
  HAL_SPI_AutonomousMode_Cfg_Struct.TriggerPolarity = SPI_TRIG_POLARITY_RISING;
  if (HAL_SPIEx_SetConfigAutonomousMode(&hspi3, &HAL_SPI_AutonomousMode_Cfg_Struct) != HAL_OK)
  {
    Error_Handler();
  }

}

static void MX_TAMP_RTC_Init(void)
{

  RTC_PrivilegeStateTypeDef privilegeState = {0};
  RTC_TamperTypeDef sTamper = {0};

  /** Enable the RTC Active Tamper
  */
  privilegeState.tampPrivilegeFull = TAMP_PRIVILEGE_FULL_YES;
  privilegeState.MonotonicCounterPrivilege = TAMP_MONOTONIC_CNT_PRIVILEGE_NO;
  if (HAL_RTCEx_PrivilegeModeSet(&hrtc, &privilegeState) != HAL_OK)
  {
    Error_Handler();
  }

  /** Enable the RTC Tamper 1
  */
  sTamper.Tamper = RTC_TAMPER_1;
  sTamper.Trigger = RTC_TAMPERTRIGGER_RISINGEDGE;
  sTamper.NoErase = RTC_TAMPER_ERASE_BACKUP_ENABLE;
  sTamper.MaskFlag = RTC_TAMPERMASK_FLAG_DISABLE;
  sTamper.Filter = RTC_TAMPERFILTER_DISABLE;
  sTamper.SamplingFrequency = RTC_TAMPERSAMPLINGFREQ_RTCCLK_DIV32768;
  sTamper.PrechargeDuration = RTC_TAMPERPRECHARGEDURATION_1RTCCLK;
  sTamper.TamperPullUp = RTC_TAMPER_PULLUP_ENABLE;
  sTamper.TimeStampOnTamperDetection = RTC_TIMESTAMPONTAMPERDETECTION_ENABLE;
  if (HAL_RTCEx_SetTamper(&hrtc, &sTamper) != HAL_OK)
  {
    Error_Handler();
  }

}

static void MX_TIM3_Init(void)
{

  TIM_MasterConfigTypeDef sMasterConfig = {0};
  TIM_IC_InitTypeDef sConfigIC = {0};

  htim3.Instance = TIM3;
  htim3.Init.Prescaler = 0;
  htim3.Init.CounterMode = TIM_COUNTERMODE_UP;
  htim3.Init.Period = 4.294967295E9;
  htim3.Init.ClockDivision = TIM_CLOCKDIVISION_DIV1;
  htim3.Init.AutoReloadPreload = TIM_AUTORELOAD_PRELOAD_DISABLE;
  if (HAL_TIM_IC_Init(&htim3) != HAL_OK)
  {
    Error_Handler();
  }
  sMasterConfig.MasterOutputTrigger = TIM_TRGO_RESET;
  sMasterConfig.MasterSlaveMode = TIM_MASTERSLAVEMODE_DISABLE;
  if (HAL_TIMEx_MasterConfigSynchronization(&htim3, &sMasterConfig) != HAL_OK)
  {
    Error_Handler();
  }
  sConfigIC.ICPolarity = TIM_INPUTCHANNELPOLARITY_RISING;
  sConfigIC.ICSelection = TIM_ICSELECTION_DIRECTTI;
  sConfigIC.ICPrescaler = TIM_ICPSC_DIV1;
  sConfigIC.ICFilter = 0;
  if (HAL_TIM_IC_ConfigChannel(&htim3, &sConfigIC, TIM_CHANNEL_1) != HAL_OK)
  {
    Error_Handler();
  }

}

static void MX_USART2_UART_Init(void)
{

  huart2.Instance = USART2;
  huart2.Init.BaudRate = 115200;
  huart2.Init.WordLength = UART_WORDLENGTH_8B;
  huart2.Init.StopBits = UART_STOPBITS_1;
  huart2.Init.Parity = UART_PARITY_NONE;
  huart2.Init.Mode = UART_MODE_TX_RX;
  huart2.Init.HwFlowCtl = UART_HWCONTROL_NONE;
  huart2.Init.OverSampling = UART_OVERSAMPLING_16;
  huart2.Init.OneBitSampling = UART_ONE_BIT_SAMPLE_DISABLE;
  huart2.Init.ClockPrescaler = UART_PRESCALER_DIV1;
  huart2.AdvancedInit.AdvFeatureInit = UART_ADVFEATURE_NO_INIT;
  if (HAL_UART_Init(&huart2) != HAL_OK)
  {
    Error_Handler();
  }
  if (HAL_UARTEx_SetTxFifoThreshold(&huart2, UART_TXFIFO_THRESHOLD_1_8) != HAL_OK)
  {
    Error_Handler();
  }
  if (HAL_UARTEx_SetRxFifoThreshold(&huart2, UART_RXFIFO_THRESHOLD_1_8) != HAL_OK)
  {
    Error_Handler();
  }
  if (HAL_UARTEx_DisableFifoMode(&huart2) != HAL_OK)
  {
    Error_Handler();
  }

}

static void MX_USART3_UART_Init(void)
{

  huart3.Instance = USART3;
  huart3.Init.BaudRate = 115200;
  huart3.Init.WordLength = UART_WORDLENGTH_8B;
  huart3.Init.StopBits = UART_STOPBITS_1;
  huart3.Init.Parity = UART_PARITY_NONE;
  huart3.Init.Mode = UART_MODE_TX_RX;
  huart3.Init.HwFlowCtl = UART_HWCONTROL_RTS_CTS;
  huart3.Init.OverSampling = UART_OVERSAMPLING_16;
  huart3.Init.OneBitSampling = UART_ONE_BIT_SAMPLE_DISABLE;
  huart3.Init.ClockPrescaler = UART_PRESCALER_DIV1;
  huart3.AdvancedInit.AdvFeatureInit = UART_ADVFEATURE_NO_INIT;
  if (HAL_UART_Init(&huart3) != HAL_OK)
  {
    Error_Handler();
  }
  if (HAL_UARTEx_SetTxFifoThreshold(&huart3, UART_TXFIFO_THRESHOLD_1_8) != HAL_OK)
  {
    Error_Handler();
  }
  if (HAL_UARTEx_SetRxFifoThreshold(&huart3, UART_RXFIFO_THRESHOLD_1_8) != HAL_OK)
  {
    Error_Handler();
  }
  if (HAL_UARTEx_DisableFifoMode(&huart3) != HAL_OK)
  {
    Error_Handler();
  }

}

static void MX_USB_OTG_FS_PCD_Init(void)
{

  hpcd_USB_OTG_FS.Instance = USB_OTG_FS;
  hpcd_USB_OTG_FS.Init.dev_endpoints = 6;
  hpcd_USB_OTG_FS.Init.phy_itface = PCD_PHY_EMBEDDED;
  hpcd_USB_OTG_FS.Init.Sof_enable = ENABLE;
  hpcd_USB_OTG_FS.Init.low_power_enable = DISABLE;
  hpcd_USB_OTG_FS.Init.lpm_enable = DISABLE;
  hpcd_USB_OTG_FS.Init.battery_charging_enable = DISABLE;
  hpcd_USB_OTG_FS.Init.use_dedicated_ep1 = DISABLE;
  hpcd_USB_OTG_FS.Init.vbus_sensing_enable = DISABLE;
  if (HAL_PCD_Init(&hpcd_USB_OTG_FS) != HAL_OK)
  {
    Error_Handler();
  }

}

static void MX_GPIO_Init(void)
{
  GPIO_InitTypeDef GPIO_InitStruct = {0};

  /* GPIO Ports Clock Enable */
  __HAL_RCC_GPIOE_CLK_ENABLE();
  __HAL_RCC_GPIOI_CLK_ENABLE();
  __HAL_RCC_GPIOG_CLK_ENABLE();
  __HAL_RCC_GPIOC_CLK_ENABLE();
  __HAL_RCC_GPIOA_CLK_ENABLE();
  __HAL_RCC_GPIOH_CLK_ENABLE();
  __HAL_RCC_GPIOB_CLK_ENABLE();
  __HAL_RCC_GPIOD_CLK_ENABLE();
  __HAL_RCC_GPIOF_CLK_ENABLE();

  /*Configure GPIO pin Output Level */
  HAL_GPIO_WritePin(GPIOH, CS_DHCX_Pin|CS_DLPC_Pin|WIFI_CS_Pin, GPIO_PIN_SET);

  /*Configure GPIO pin Output Level */
  HAL_GPIO_WritePin(GPIOI, EX_SPI_NSS_Pin|CS_ICLX_Pin, GPIO_PIN_SET);

  /*Configure GPIO pin Output Level */
  HAL_GPIO_WritePin(BLE_SPI_CS_GPIO_Port, BLE_SPI_CS_Pin, GPIO_PIN_SET);

  /*Configure GPIO pin Output Level */
  HAL_GPIO_WritePin(CS_DWB_GPIO_Port, CS_DWB_Pin, GPIO_PIN_SET);

  /*Configure GPIO pin : INT_HTS_Pin */
  GPIO_InitStruct.Pin = INT_HTS_Pin;
  GPIO_InitStruct.Mode = GPIO_MODE_IT_RISING;
  GPIO_InitStruct.Pull = GPIO_NOPULL;
  HAL_GPIO_Init(INT_HTS_GPIO_Port, &GPIO_InitStruct);

  /*Configure GPIO pins : WIFI_FLOW_Pin SD_DETECT_Pin INT_EX_Pin INT_EXG5_Pin */
  GPIO_InitStruct.Pin = WIFI_FLOW_Pin|SD_DETECT_Pin|INT_EX_Pin|INT_EXG5_Pin;
  GPIO_InitStruct.Mode = GPIO_MODE_ANALOG;
  GPIO_InitStruct.Pull = GPIO_NOPULL;
  HAL_GPIO_Init(GPIOG, &GPIO_InitStruct);

  /*Configure GPIO pins : CS_DHCX_Pin CS_DLPC_Pin WIFI_CS_Pin */
  GPIO_InitStruct.Pin = CS_DHCX_Pin|CS_DLPC_Pin|WIFI_CS_Pin;
  GPIO_InitStruct.Mode = GPIO_MODE_OUTPUT_PP;
  GPIO_InitStruct.Pull = GPIO_NOPULL;
  GPIO_InitStruct.Speed = GPIO_SPEED_FREQ_LOW;
  HAL_GPIO_Init(GPIOH, &GPIO_InitStruct);

  /*Configure GPIO pins : DCDC_2_EN_Pin SPI2_MISO_p2_Pin */
  GPIO_InitStruct.Pin = DCDC_2_EN_Pin|SPI2_MISO_p2_Pin;
  GPIO_InitStruct.Mode = GPIO_MODE_ANALOG;
  GPIO_InitStruct.Pull = GPIO_NOPULL;
  HAL_GPIO_Init(GPIOI, &GPIO_InitStruct);

  /*Configure GPIO pins : C_EN_Pin INT_EXD15_Pin BLE_RST_Pin WIFI_BOOT_Pin */
  GPIO_InitStruct.Pin = C_EN_Pin|INT_EXD15_Pin|BLE_RST_Pin|WIFI_BOOT_Pin;
  GPIO_InitStruct.Mode = GPIO_MODE_ANALOG;
  GPIO_InitStruct.Pull = GPIO_NOPULL;
  HAL_GPIO_Init(GPIOD, &GPIO_InitStruct);

  /*Configure GPIO pins : EX_SPI_NSS_Pin CS_ICLX_Pin */
  GPIO_InitStruct.Pin = EX_SPI_NSS_Pin|CS_ICLX_Pin;
  GPIO_InitStruct.Mode = GPIO_MODE_OUTPUT_PP;
  GPIO_InitStruct.Pull = GPIO_NOPULL;
  GPIO_InitStruct.Speed = GPIO_SPEED_FREQ_LOW;
  HAL_GPIO_Init(GPIOI, &GPIO_InitStruct);

  /*Configure GPIO pins : LED1_Pin BOOT0_Pin LED2_Pin STSAFE_RESET_Pin */
  GPIO_InitStruct.Pin = LED1_Pin|BOOT0_Pin|LED2_Pin|STSAFE_RESET_Pin;
  GPIO_InitStruct.Mode = GPIO_MODE_ANALOG;
  GPIO_InitStruct.Pull = GPIO_NOPULL;
  HAL_GPIO_Init(GPIOH, &GPIO_InitStruct);

  /*Configure GPIO pin : BLE_SPI_CS_Pin */
  GPIO_InitStruct.Pin = BLE_SPI_CS_Pin;
  GPIO_InitStruct.Mode = GPIO_MODE_OUTPUT_PP;
  GPIO_InitStruct.Pull = GPIO_NOPULL;
  GPIO_InitStruct.Speed = GPIO_SPEED_FREQ_LOW;
  HAL_GPIO_Init(BLE_SPI_CS_GPIO_Port, &GPIO_InitStruct);

  /*Configure GPIO pins : USR_BUTTON_Pin WIFI_NOTIFY_Pin */
  GPIO_InitStruct.Pin = USR_BUTTON_Pin|WIFI_NOTIFY_Pin;
  GPIO_InitStruct.Mode = GPIO_MODE_IT_RISING;
  GPIO_InitStruct.Pull = GPIO_NOPULL;
  HAL_GPIO_Init(GPIOE, &GPIO_InitStruct);

  /*Configure GPIO pins : INT1_DHCX_Pin NFC_INT_Pin */
  GPIO_InitStruct.Pin = INT1_DHCX_Pin|NFC_INT_Pin;
  GPIO_InitStruct.Mode = GPIO_MODE_IT_RISING;
  GPIO_InitStruct.Pull = GPIO_NOPULL;
  HAL_GPIO_Init(GPIOB, &GPIO_InitStruct);

  /*Configure GPIO pins : GPIO2_EX_Pin BLE_TEST9_Pin BLE_TEST8_Pin */
  GPIO_InitStruct.Pin = GPIO2_EX_Pin|BLE_TEST9_Pin|BLE_TEST8_Pin;
  GPIO_InitStruct.Mode = GPIO_MODE_ANALOG;
  GPIO_InitStruct.Pull = GPIO_NOPULL;
  HAL_GPIO_Init(GPIOF, &GPIO_InitStruct);

  /*Configure GPIO pins : INT1_DLPC_Pin INT2_DLPC_Pin INT_MAG_Pin INT_STT_Pin
                           INT1_ICLX_Pin INT2_DHCX_Pin BLE_INT_Pin INT2_ICLX_Pin
                           INT1_DWB_Pin */
  GPIO_InitStruct.Pin = INT1_DLPC_Pin|INT2_DLPC_Pin|INT_MAG_Pin|INT_STT_Pin
                          |INT1_ICLX_Pin|INT2_DHCX_Pin|BLE_INT_Pin|INT2_ICLX_Pin
                          |INT1_DWB_Pin;
  GPIO_InitStruct.Mode = GPIO_MODE_IT_RISING;
  GPIO_InitStruct.Pull = GPIO_NOPULL;
  HAL_GPIO_Init(GPIOF, &GPIO_InitStruct);

  /*Configure GPIO pin : SW_SEL_Pin */
  GPIO_InitStruct.Pin = SW_SEL_Pin;
  GPIO_InitStruct.Mode = GPIO_MODE_ANALOG;
  GPIO_InitStruct.Pull = GPIO_NOPULL;
  HAL_GPIO_Init(SW_SEL_GPIO_Port, &GPIO_InitStruct);

  /*Configure GPIO pins : uC_ADC_BATT_Pin ADC_EX_Pin */
  GPIO_InitStruct.Pin = uC_ADC_BATT_Pin|ADC_EX_Pin;
  GPIO_InitStruct.Mode = GPIO_MODE_ANALOG;
  GPIO_InitStruct.Pull = GPIO_NOPULL;
  HAL_GPIO_Init(GPIOC, &GPIO_InitStruct);

  /*Configure GPIO pin : CS_DWB_Pin */
  GPIO_InitStruct.Pin = CS_DWB_Pin;
  GPIO_InitStruct.Mode = GPIO_MODE_OUTPUT_PP;
  GPIO_InitStruct.Pull = GPIO_NOPULL;
  GPIO_InitStruct.Speed = GPIO_SPEED_FREQ_LOW;
  HAL_GPIO_Init(CS_DWB_GPIO_Port, &GPIO_InitStruct);

  /*Configure GPIO pin : BUTTON_PWR_Pin */
  GPIO_InitStruct.Pin = BUTTON_PWR_Pin;
  GPIO_InitStruct.Mode = GPIO_MODE_IT_RISING;
  GPIO_InitStruct.Pull = GPIO_NOPULL;
  HAL_GPIO_Init(BUTTON_PWR_GPIO_Port, &GPIO_InitStruct);

  /*Configure GPIO pins : SPI2_MOSI_p2_Pin GPIO1_EX_Pin */
  GPIO_InitStruct.Pin = SPI2_MOSI_p2_Pin|GPIO1_EX_Pin;
  GPIO_InitStruct.Mode = GPIO_MODE_ANALOG;
  GPIO_InitStruct.Pull = GPIO_NOPULL;
  HAL_GPIO_Init(GPIOB, &GPIO_InitStruct);

  /*Configure GPIO pins : LDO_EN_Pin WIFI_EN_Pin */
  GPIO_InitStruct.Pin = LDO_EN_Pin|WIFI_EN_Pin;
  GPIO_InitStruct.Mode = GPIO_MODE_ANALOG;
  GPIO_InitStruct.Pull = GPIO_NOPULL;
  HAL_GPIO_Init(GPIOE, &GPIO_InitStruct);

  /* EXTI interrupt init*/
  HAL_NVIC_SetPriority(EXTI0_IRQn, 7, 0);
  HAL_NVIC_EnableIRQ(EXTI0_IRQn);

  HAL_NVIC_SetPriority(EXTI1_IRQn, 7, 0);
  HAL_NVIC_EnableIRQ(EXTI1_IRQn);

  HAL_NVIC_SetPriority(EXTI2_IRQn, 7, 0);
  HAL_NVIC_EnableIRQ(EXTI2_IRQn);

  HAL_NVIC_SetPriority(EXTI3_IRQn, 7, 0);
  HAL_NVIC_EnableIRQ(EXTI3_IRQn);

  HAL_NVIC_SetPriority(EXTI4_IRQn, 7, 0);
  HAL_NVIC_EnableIRQ(EXTI4_IRQn);

  HAL_NVIC_SetPriority(EXTI5_IRQn, 7, 0);
  HAL_NVIC_EnableIRQ(EXTI5_IRQn);

  HAL_NVIC_SetPriority(EXTI6_IRQn, 7, 0);
  HAL_NVIC_EnableIRQ(EXTI6_IRQn);

  HAL_NVIC_SetPriority(EXTI7_IRQn, 7, 0);
  HAL_NVIC_EnableIRQ(EXTI7_IRQn);

  HAL_NVIC_SetPriority(EXTI8_IRQn, 7, 0);
  HAL_NVIC_EnableIRQ(EXTI8_IRQn);

  HAL_NVIC_SetPriority(EXTI9_IRQn, 7, 0);
  HAL_NVIC_EnableIRQ(EXTI9_IRQn);

  HAL_NVIC_SetPriority(EXTI10_IRQn, 7, 0);
  HAL_NVIC_EnableIRQ(EXTI10_IRQn);

  HAL_NVIC_SetPriority(EXTI11_IRQn, 7, 0);
  HAL_NVIC_EnableIRQ(EXTI11_IRQn);

  HAL_NVIC_SetPriority(EXTI13_IRQn, 7, 0);
  HAL_NVIC_EnableIRQ(EXTI13_IRQn);

  HAL_NVIC_SetPriority(EXTI14_IRQn, 7, 0);
  HAL_NVIC_EnableIRQ(EXTI14_IRQn);

}

void Error_Handler(void)
{
  __disable_irq();
  while (1)
  {
  }
}
